# STM32F413ZHT7 register map
File version: 1.0
Registers are 32-bit, access not given, reset 0x0 unless marked. A register's access mark holds for its fields unless they carry their own. Offsets are from the block's base; [hi:lo] are bit positions; {n}, {i} and the like mark numbered series.

## FMPI2C1
Base 0x40006000
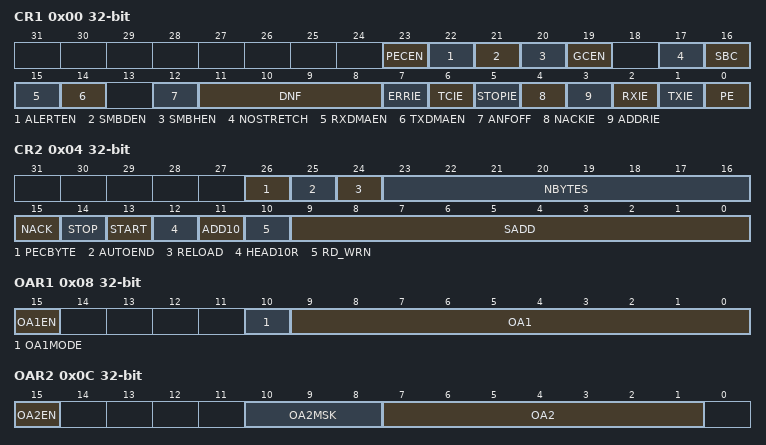
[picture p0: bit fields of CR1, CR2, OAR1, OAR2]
0x00 CR1
  [23] PECEN, [22] ALERTEN, [21] SMBDEN, [20] SMBHEN, [19] GCEN, [17] NOSTRETCH, [16] SBC, [15] RXDMAEN, [14] TXDMAEN, [12] ANFOFF, [11:8] DNF, [7] ERRIE, [6] TCIE, [5] STOPIE, [4] NACKIE, [3] ADDRIE, [2] RXIE, [1] TXIE, [0] PE
0x04 CR2
  [26] PECBYTE, [25] AUTOEND, [24] RELOAD, [23:16] NBYTES, [15] NACK, [14] STOP, [13] START, [12] HEAD10R, [11] ADD10, [10] RD_WRN, [9:0] SADD
0x08 OAR1
  [15] OA1EN, [10] OA1MODE, [9:0] OA1
0x0C OAR2
  [15] OA2EN, [10:8] OA2MSK, [7:1] OA2
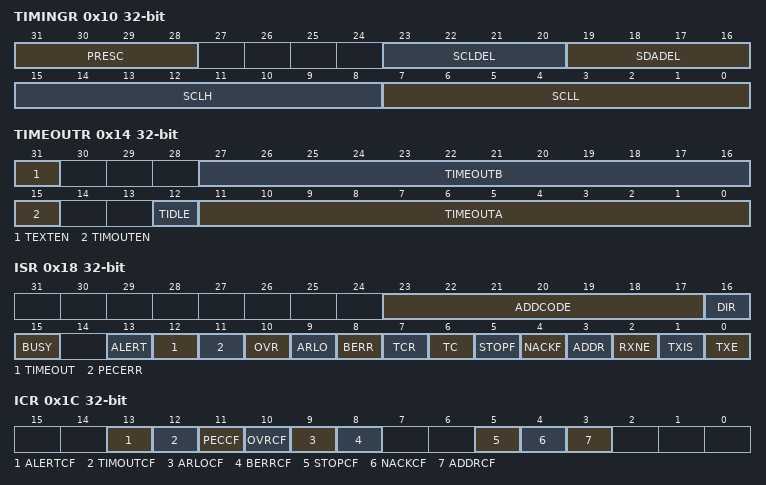
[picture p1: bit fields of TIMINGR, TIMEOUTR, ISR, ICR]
0x10 TIMINGR
  [31:28] PRESC, [23:20] SCLDEL, [19:16] SDADEL, [15:8] SCLH, [7:0] SCLL
0x14 TIMEOUTR
  [31] TEXTEN, [27:16] TIMEOUTB, [15] TIMOUTEN, [12] TIDLE, [11:0] TIMEOUTA
0x18 ISR
  [23:17] ADDCODE, [16] DIR, [15] BUSY, [13] ALERT, [12] TIMEOUT, [11] PECERR, [10] OVR, [9] ARLO, [8] BERR, [7] TCR, [6] TC, [5] STOPF, [4] NACKF, [3] ADDR, [2] RXNE, [1] TXIS, [0] TXE
0x1C ICR
  [13] ALERTCF, [12] TIMOUTCF, [11] PECCF, [10] OVRCF, [9] ARLOCF, [8] BERRCF, [5] STOPCF, [4] NACKCF, [3] ADDRCF
0x20 PECR
  [7:0] PEC
0x24 RXDR
  [7:0] RXDATA
0x28 TXDR
  [7:0] TXDATA

## PWR
Base 0x40007000
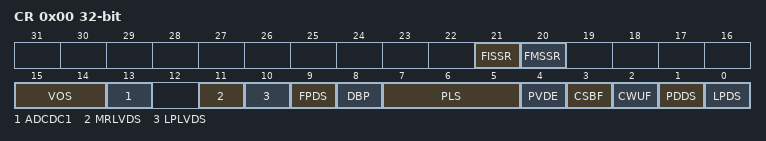
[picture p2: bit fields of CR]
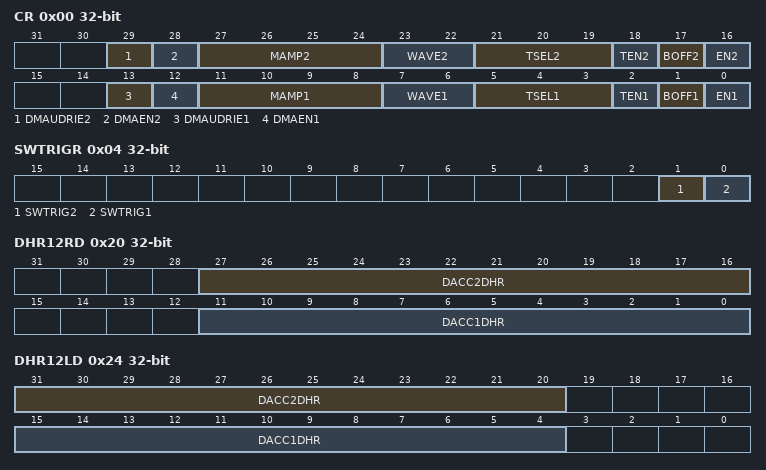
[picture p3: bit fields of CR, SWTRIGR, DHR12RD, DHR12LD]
0x00 CR
  [21] FISSR, [20] FMSSR, [15:14] VOS, [13] ADCDC1, [11] MRLVDS, [10] LPLVDS, [9] FPDS, [8] DBP, [7:5] PLS, [4] PVDE, [3] CSBF, [2] CWUF, [1] PDDS, [0] LPDS
0x04 CSR
  [14] VOSRDY, [9] BRE, [8] EWUP1, [7] EWUP2, [8:6] EWUP3, [3] BRR, [2] PVDO, [1] SBF, [0] WUF

## DAC1
Base 0x40007400
0x00 CR
  [29] DMAUDRIE2, [28] DMAEN2, [27:24] MAMP2, [23:22] WAVE2, [21:19] TSEL2, [18] TEN2, [17] BOFF2, [16] EN2, [13] DMAUDRIE1, [12] DMAEN1, [11:8] MAMP1, [7:6] WAVE1, [5:3] TSEL1, [2] TEN1, [1] BOFF1, [0] EN1
0x04 SWTRIGR
  [1] SWTRIG2, [0] SWTRIG1
0x08 DHR12R1
  [11:0] DACC1DHR
0x0C DHR12L1
  [15:4] DACC1DHR
0x10 DHR8R1
  [7:0] DACC1DHR
0x14 DHR12R2
  [11:0] DACC2DHR
0x18 DHR12L2
  [15:4] DACC2DHR
0x1C DHR8R2
  [7:0] DACC2DHR
0x20 DHR12RD
  [27:16] DACC2DHR, [11:0] DACC1DHR
0x24 DHR12LD
  [31:20] DACC2DHR, [15:4] DACC1DHR
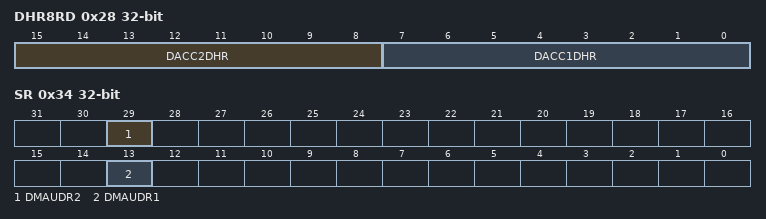
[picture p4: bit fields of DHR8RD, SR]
0x28 DHR8RD
  [15:8] DACC2DHR, [7:0] DACC1DHR
0x2C DOR1
  [11:0] DACC1DOR
0x30 DOR2
  [11:0] DACC2DOR
0x34 SR
  [29] DMAUDR2, [13] DMAUDR1

## ADC1
Base 0x40012000
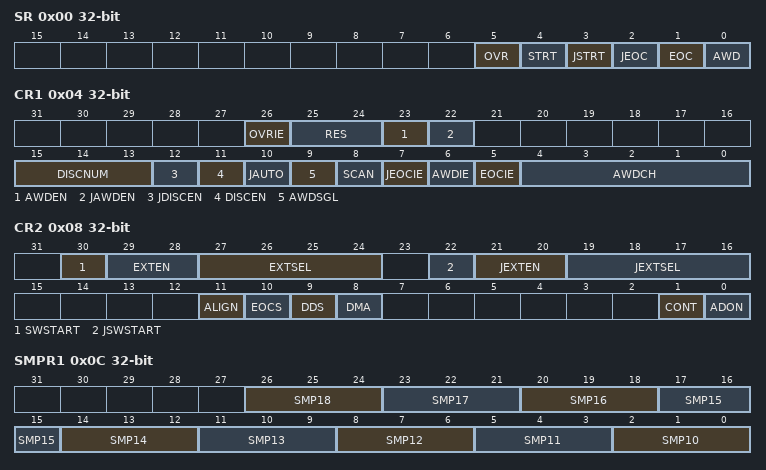
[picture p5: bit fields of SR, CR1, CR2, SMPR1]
0x00 SR
  [5] OVR, [4] STRT, [3] JSTRT, [2] JEOC, [1] EOC, [0] AWD
0x04 CR1
  [26] OVRIE, [25:24] RES, [23] AWDEN, [22] JAWDEN, [15:13] DISCNUM, [12] JDISCEN, [11] DISCEN, [10] JAUTO, [9] AWDSGL, [8] SCAN, [7] JEOCIE, [6] AWDIE, [5] EOCIE, [4:0] AWDCH
0x08 CR2
  [30] SWSTART, [29:28] EXTEN, [27:24] EXTSEL, [22] JSWSTART, [21:20] JEXTEN, [19:16] JEXTSEL, [11] ALIGN, [10] EOCS, [9] DDS, [8] DMA, [1] CONT, [0] ADON
0x0C SMPR1
  [3n-28:3n-30] SMP{n} (n=10..18)
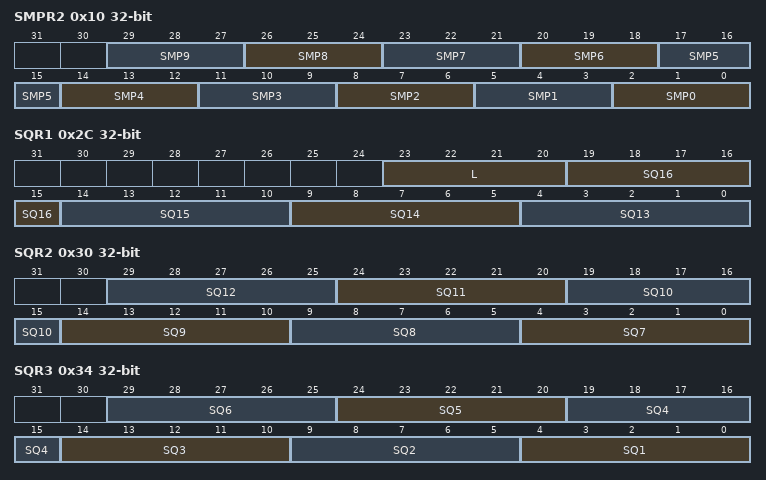
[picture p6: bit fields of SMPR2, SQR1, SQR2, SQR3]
0x10 SMPR2
  [3n+2:3n] SMP{n} (n=0..9)
{0x10+4i} JOFR{i} (i=1..4)
  [11:0] JOFFSET{i}
0x24 HTR
  [11:0] HT
0x28 LTR
  [11:0] LT
0x2C SQR1
  [23:20] L, [5n-61:5n-65] SQ{n} (n=13..16)
0x30 SQR2
  [5n-31:5n-35] SQ{n} (n=7..12)
0x34 SQR3
  [5n-1:5n-5] SQ{n} (n=1..6)
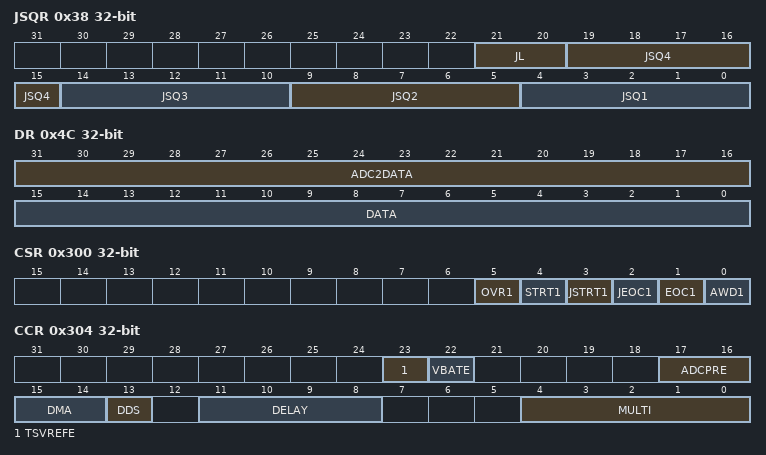
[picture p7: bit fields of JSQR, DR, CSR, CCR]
0x38 JSQR
  [21:20] JL, [5n-1:5n-5] JSQ{n} (n=1..4)
{0x38+4i} JDR{i} (i=1..4)
  [15:0] JDATA
0x4C DR
  [31:16] ADC2DATA, [15:0] DATA
0x300 CSR
  [5] OVR1, [4] STRT1, [3] JSTRT1, [2] JEOC1, [1] EOC1, [0] AWD1
0x304 CCR
  [23] TSVREFE, [22] VBATE, [17:16] ADCPRE, [15:14] DMA, [13] DDS, [11:8] DELAY, [4:0] MULTI
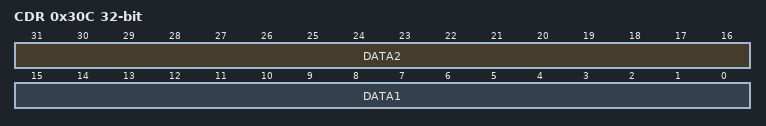
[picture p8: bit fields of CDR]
0x30C CDR
  [31:16] DATA2, [15:0] DATA1

## SDIO
Base 0x40012C00
0x00 POWER
  [1:0] PWRCTRL
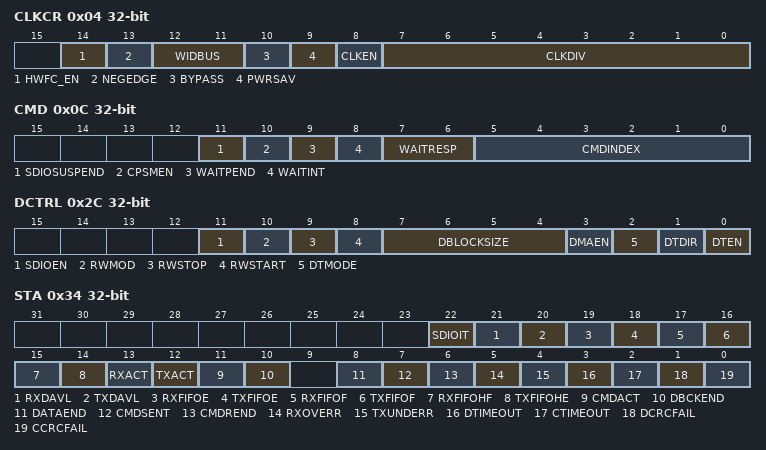
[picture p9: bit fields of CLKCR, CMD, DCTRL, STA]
0x04 CLKCR
  [14] HWFC_EN, [13] NEGEDGE, [12:11] WIDBUS, [10] BYPASS, [9] PWRSAV, [8] CLKEN, [7:0] CLKDIV
0x08 ARG
  [31:0] CMDARG
0x0C CMD
  [11] SDIOSUSPEND, [10] CPSMEN, [9] WAITPEND, [8] WAITINT, [7:6] WAITRESP, [5:0] CMDINDEX
0x10 RESPCMD
  [5:0] RESPCMD
{0x10+4i} RESP{i} (i=1..4)
  [31:0] CARDSTATUS{i}
0x24 DTIMER
  [31:0] DATATIME
0x28 DLEN
  [24:0] DATALENGTH
0x2C DCTRL
  [11] SDIOEN, [10] RWMOD, [9] RWSTOP, [8] RWSTART, [7:4] DBLOCKSIZE, [3] DMAEN, [2] DTMODE, [1] DTDIR, [0] DTEN
0x30 DCOUNT
  [24:0] DATACOUNT
0x34 STA
  [22] SDIOIT, [21] RXDAVL, [20] TXDAVL, [19] RXFIFOE, [18] TXFIFOE, [17] RXFIFOF, [16] TXFIFOF, [15] RXFIFOHF, [14] TXFIFOHE, [13] RXACT, [12] TXACT, [11] CMDACT, [10] DBCKEND, [8] DATAEND, [7] CMDSENT, [6] CMDREND, [5] RXOVERR, [4] TXUNDERR, [3] DTIMEOUT, [2] CTIMEOUT, [1] DCRCFAIL, [0] CCRCFAIL
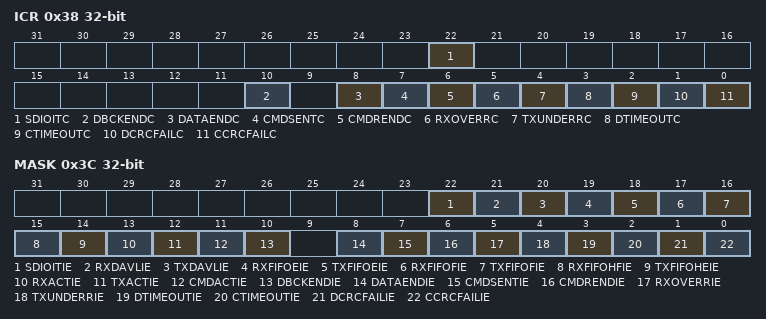
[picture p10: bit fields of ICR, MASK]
0x38 ICR
  [22] SDIOITC, [10] DBCKENDC, [8] DATAENDC, [7] CMDSENTC, [6] CMDRENDC, [5] RXOVERRC, [4] TXUNDERRC, [3] DTIMEOUTC, [2] CTIMEOUTC, [1] DCRCFAILC, [0] CCRCFAILC
0x3C MASK
  [22] SDIOITIE, [21] RXDAVLIE, [20] TXDAVLIE, [19] RXFIFOEIE, [18] TXFIFOEIE, [17] RXFIFOFIE, [16] TXFIFOFIE, [15] RXFIFOHFIE, [14] TXFIFOHEIE, [13] RXACTIE, [12] TXACTIE, [11] CMDACTIE, [10] DBCKENDIE, [8] DATAENDIE, [7] CMDSENTIE, [6] CMDRENDIE, [5] RXOVERRIE, [4] TXUNDERRIE, [3] DTIMEOUTIE, [2] CTIMEOUTIE, [1] DCRCFAILIE, [0] CCRCFAILIE
0x48 FIFOCNT
  [23:0] FIFOCOUNT
0x80 FIFO
  [31:0] FIFODATA
